# VPAC0_DRU_UTC_VPAC0_DRU_MMR_CFG_DRU_DRU register map
Vendor: Texas Instruments
Peripheral module from a debugger description file (folder J7ES).
Registers are 64-bit, read-only, reset 0x662C0900 unless marked. A register's access mark holds for its fields unless they carry their own. Offsets are as the file gives them; lines under a group give offsets from that group; [hi:lo] are bit positions; {n}, {i} and the like mark numbered series; 'fields as' and 'values as' point back to an identical list; <NAME> marks a mode.

## VPAC0_DRU_UTC_VPAC0_DRU_MMR_CFG_DRU_DRU
0x00 VPAC_UTC0_RT_DRU_PID — Peripheral ID Register
  [31:0] REVISION — PID Revision
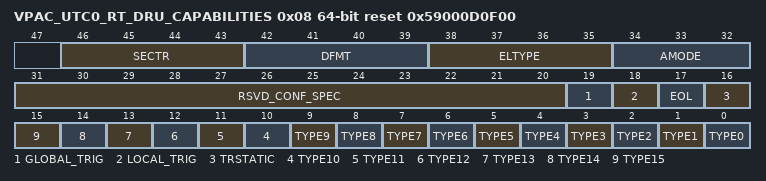
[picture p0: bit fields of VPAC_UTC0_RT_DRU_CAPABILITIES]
0x08 VPAC_UTC0_RT_DRU_CAPABILITIES reset 0x59000D0F00 — DRU Capabilities: Lists the capabilities of the channel for TR TYPE and formatting functions
  [46:43] SECTR — Maximum second TR function that is supported
  [42:39] DFMT — Maximum data reformatting function that is supported
  [38:35] ELTYPE — Maximum element type value that is supported
  [34:32] AMODE — The maximum AMODE that is supported.
  [31:20] RSVD_CONF_SPEC — Reserved for Configuration Specific Features.
  [19] GLOBAL_TRIG — Global Triggers 0 and 1 are supported
  [18] LOCAL_TRIG — Dedicated Local Trigger is supported
  [17] EOL — EOL Field is supported
  [16] TRSTATIC — STATIC Field is supported
  [n] TYPE{n} (n=0..15) — Type {n} TR is supported
